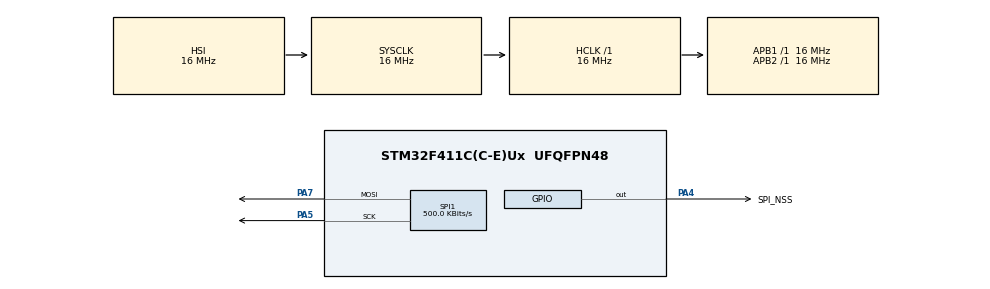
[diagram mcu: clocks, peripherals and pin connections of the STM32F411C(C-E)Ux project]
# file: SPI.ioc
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Mcu.Family=STM32F4
Mcu.Name=STM32F411C(C-E)Ux
Mcu.Package=UFQFPN48
NVIC.PriorityGroup=NVIC_PRIORITYGROUP_4
PA4.GPIO_Label=SPI_NSS
PA4.GPIO_Speed=GPIO_SPEED_FREQ_VERY_HIGH
PA4.Signal=GPIO_Output
PA5.Mode=TX_Only_Simplex_Unidirect_Master
PA5.Signal=SPI1_SCK
PA7.Mode=TX_Only_Simplex_Unidirect_Master
PA7.Signal=SPI1_MOSI
ProjectManager.HeapSize=0x200
ProjectManager.StackSize=0x400
ProjectManager.TargetToolchain=STM32CubeIDE
RCC.AHBFreq_Value=16000000
RCC.APB1Freq_Value=16000000
RCC.APB2Freq_Value=16000000
RCC.CortexFreq_Value=16000000
RCC.HSE_VALUE=25000000
RCC.HSI_VALUE=16000000
RCC.LSE_VALUE=32768
RCC.SYSCLKFreq_VALUE=16000000
RCC.VCOOutputFreq_Value=192000000
SPI1.BaudRatePrescaler=SPI_BAUDRATEPRESCALER_32
SPI1.CLKPhase=SPI_PHASE_2EDGE
SPI1.CLKPolarity=SPI_POLARITY_HIGH
SPI1.CalculateBaudRate=500.0 KBits/s
SPI1.DataSize=SPI_DATASIZE_16BIT
SPI1.Direction=SPI_DIRECTION_2LINES
SPI1.Mode=SPI_MODE_MASTER
SPI1.VirtualType=VM_MASTER
board=custom

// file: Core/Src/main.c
/* USER CODE BEGIN Header */
/**
  ******************************************************************************
  * @file           : main.c
  A4 NSS
  ******************************************************************************
  * @attention
  *
  * Copyright (c) 2026 STMicroelectronics.
  * All rights reserved.
  *
  * This software is licensed under terms that can be found in the LICENSE file
  * in the root directory of this software component.
  * If no LICENSE file comes with this software, it is provided AS-IS.
  *
  ******************************************************************************
A7 MOSI
A4 NSS
A5 SCK
  */

/* USER CODE END Header */
#include "main.h"

/* USER CODE BEGIN PD */
#define SPI_CS_GPIO_Port GPIOA
#define SPI_CS_Pin GPIO_PIN_4

/* USER CODE END PD */

SPI_HandleTypeDef hspi1;

/* USER CODE BEGIN PV */
uint16_t spi_tx_word = 0x9885;

/* USER CODE END PV */

void SystemClock_Config(void);
static void MX_GPIO_Init(void);
static void MX_SPI1_Init(void);

int main(void)
{

  /* MCU Configuration--------------------------------------------------------*/

  /* Reset of all peripherals, Initializes the Flash interface and the Systick. */
  HAL_Init();

  /* Configure the system clock */
  SystemClock_Config();

  /* Initialize all configured peripherals */
  MX_GPIO_Init();
  MX_SPI1_Init();
  /* USER CODE BEGIN 2 */
  HAL_GPIO_WritePin(SPI_NSS_GPIO_Port, SPI_NSS_Pin, GPIO_PIN_SET);

  /* USER CODE END 2 */

  /* Infinite loop */
  while (1)
  {

    /* USER CODE BEGIN 3 */
HAL_GPIO_WritePin(SPI_NSS_GPIO_Port, SPI_NSS_Pin, GPIO_PIN_RESET);
HAL_SPI_Transmit(&hspi1, (uint8_t *)&spi_tx_word, 1, HAL_MAX_DELAY);
HAL_GPIO_WritePin(SPI_NSS_GPIO_Port, SPI_NSS_Pin, GPIO_PIN_SET);
  }
  /* USER CODE END 3 */
}

void SystemClock_Config(void)
{
  RCC_OscInitTypeDef RCC_OscInitStruct = {0};
  RCC_ClkInitTypeDef RCC_ClkInitStruct = {0};

  /** Configure the main internal regulator output voltage
  */
  __HAL_RCC_PWR_CLK_ENABLE();
  __HAL_PWR_VOLTAGESCALING_CONFIG(PWR_REGULATOR_VOLTAGE_SCALE1);

  /** Initializes the RCC Oscillators according to the specified parameters
  * in the RCC_OscInitTypeDef structure.
  */
  RCC_OscInitStruct.OscillatorType = RCC_OSCILLATORTYPE_HSI;
  RCC_OscInitStruct.HSIState = RCC_HSI_ON;
  RCC_OscInitStruct.HSICalibrationValue = RCC_HSICALIBRATION_DEFAULT;
  RCC_OscInitStruct.PLL.PLLState = RCC_PLL_NONE;
  if (HAL_RCC_OscConfig(&RCC_OscInitStruct) != HAL_OK)
  {
    Error_Handler();
  }

  /** Initializes the CPU, AHB and APB buses clocks
  */
  RCC_ClkInitStruct.ClockType = RCC_CLOCKTYPE_HCLK|RCC_CLOCKTYPE_SYSCLK
                              |RCC_CLOCKTYPE_PCLK1|RCC_CLOCKTYPE_PCLK2;
  RCC_ClkInitStruct.SYSCLKSource = RCC_SYSCLKSOURCE_HSI;
  RCC_ClkInitStruct.AHBCLKDivider = RCC_SYSCLK_DIV1;
  RCC_ClkInitStruct.APB1CLKDivider = RCC_HCLK_DIV1;
  RCC_ClkInitStruct.APB2CLKDivider = RCC_HCLK_DIV1;

  if (HAL_RCC_ClockConfig(&RCC_ClkInitStruct, FLASH_LATENCY_0) != HAL_OK)
  {
    Error_Handler();
  }
}

static void MX_SPI1_Init(void)
{

  /* SPI1 parameter configuration*/
  hspi1.Instance = SPI1;
  hspi1.Init.Mode = SPI_MODE_MASTER;
  hspi1.Init.Direction = SPI_DIRECTION_2LINES;
  hspi1.Init.DataSize = SPI_DATASIZE_16BIT;
  hspi1.Init.CLKPolarity = SPI_POLARITY_HIGH;
  hspi1.Init.CLKPhase = SPI_PHASE_2EDGE;
  hspi1.Init.NSS = SPI_NSS_SOFT;
  hspi1.Init.BaudRatePrescaler = SPI_BAUDRATEPRESCALER_32;
  hspi1.Init.FirstBit = SPI_FIRSTBIT_MSB;
  hspi1.Init.TIMode = SPI_TIMODE_DISABLE;
  hspi1.Init.CRCCalculation = SPI_CRCCALCULATION_DISABLE;
  hspi1.Init.CRCPolynomial = 10;
  if (HAL_SPI_Init(&hspi1) != HAL_OK)
  {
    Error_Handler();
  }

}

static void MX_GPIO_Init(void)
{
  GPIO_InitTypeDef GPIO_InitStruct = {0};

  /* GPIO Ports Clock Enable */
  __HAL_RCC_GPIOA_CLK_ENABLE();

  /*Configure GPIO pin Output Level */
  HAL_GPIO_WritePin(SPI_NSS_GPIO_Port, SPI_NSS_Pin, GPIO_PIN_RESET);

  /*Configure GPIO pin : SPI_NSS_Pin */
  GPIO_InitStruct.Pin = SPI_NSS_Pin;
  GPIO_InitStruct.Mode = GPIO_MODE_OUTPUT_PP;
  GPIO_InitStruct.Pull = GPIO_NOPULL;
  GPIO_InitStruct.Speed = GPIO_SPEED_FREQ_VERY_HIGH;
  HAL_GPIO_Init(SPI_NSS_GPIO_Port, &GPIO_InitStruct);

}

void Error_Handler(void)
{
  __disable_irq();
  while (1)
  {
  }
}
